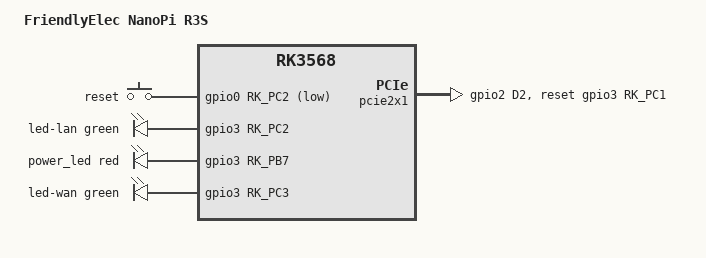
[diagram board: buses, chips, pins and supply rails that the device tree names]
// SPDX-License-Identifier: GPL-2.0-or-later OR MIT
/*
 * Copyright (c) 2022 FriendlyElec Computer Tech. Co., Ltd.
 * (http://www.friendlyelec.com)
 *
 * Copyright (c) 2023 Tianling Shen <cnsztl@gmail.com>
 */

/dts-v1/;
#include "rk3566-nanopi-r3s.dtsi"

/ {
	model = "FriendlyElec NanoPi R3S";
	compatible = "friendlyarm,nanopi-r3s", "rockchip,rk3568";

	gpio-keys {
		compatible = "gpio-keys";
		pinctrl-names = "default";
		pinctrl-0 = <&reset_button_pin>;

		button-reset {
			debounce-interval = <50>;
			gpios = <&gpio0 RK_PC2 GPIO_ACTIVE_LOW>;
			label = "reset";
			linux,code = <KEY_RESTART>;
		};
	};

	gpio-leds {
		compatible = "gpio-leds";
		pinctrl-names = "default";
		pinctrl-0 = <&lan_led_pin>, <&power_led_pin>, <&wan_led_pin>;

		led-lan {
			color = <LED_COLOR_ID_GREEN>;
			function = LED_FUNCTION_LAN;
			gpios = <&gpio3 RK_PC2 GPIO_ACTIVE_HIGH>;
		};

		power_led: led-power {
			color = <LED_COLOR_ID_RED>;
			function = LED_FUNCTION_POWER;
			linux,default-trigger = "heartbeat";
			gpios = <&gpio3 RK_PB7 GPIO_ACTIVE_HIGH>;
		};

		led-wan {
			color = <LED_COLOR_ID_GREEN>;
			function = LED_FUNCTION_WAN;
			gpios = <&gpio3 RK_PC3 GPIO_ACTIVE_HIGH>;
		};
	};
};
&pcie2x1 {
	pinctrl-names = "default";
	pinctrl-0 = <&pcie20_reset_pin>;
	reset-gpios = <&gpio3 RK_PC1 GPIO_ACTIVE_HIGH>;
	status = "okay";
};
&pinctrl {
	gpio-leds {
		lan_led_pin: lan-led-pin {
			rockchip,pins = <3 RK_PA3 RK_FUNC_GPIO &pcfg_pull_none>;
		};

		power_led_pin: power-led-pin {
			rockchip,pins = <0 RK_PB7 RK_FUNC_GPIO &pcfg_pull_none>;
		};

		wan_led_pin: wan-led-pin {
			rockchip,pins = <3 RK_PC3 RK_FUNC_GPIO &pcfg_pull_none>;
		};

	};

	pcie {
		pcie20_reset_pin: pcie20-reset-pin {
			rockchip,pins = <2 RK_PD2 RK_FUNC_GPIO &pcfg_pull_up>;
		};
	};

	rockchip-key {
		reset_button_pin: reset-button-pin {
			rockchip,pins = <0 RK_PC2 RK_FUNC_GPIO &pcfg_pull_up>;
		};
	};
};
